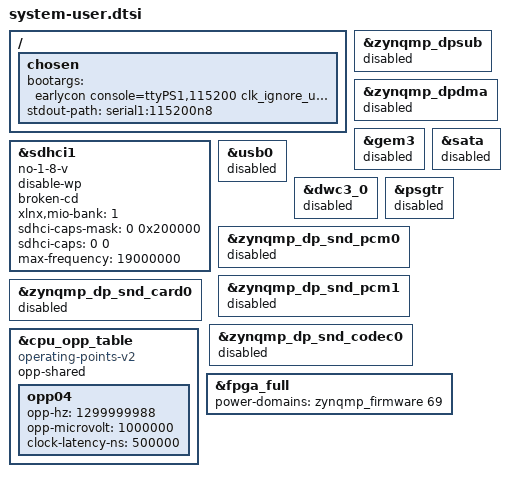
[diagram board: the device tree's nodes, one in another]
/include/ "system-conf.dtsi"
/ {
	chosen {
                bootargs = "earlycon console=ttyPS1,115200 clk_ignore_unused root=/dev/mmcblk1p2 init_fatal_sh=1 cma=1000M ";
                stdout-path = "serial1:115200n8";
        };
};

&sdhci1 { /* FIXME - on CC - MIO 39 - 51 */
    	status = "okay";
    	no-1-8-v;
    	disable-wp;
    	broken-cd;
    	xlnx,mio-bank = <1>;
    	/* Do not run SD in HS mode from bootloader */
    	sdhci-caps-mask = <0 0x200000>;
    	sdhci-caps = <0 0>;
    	max-frequency = <19000000>;
};
    
&zynqmp_dpsub {
	status = "disabled";
	
};

&zynqmp_dpdma {
	status = "disabled";
};

&gem3 {
	status = "disabled";
};

&sata {
	status = "disabled";
};

&usb0 {
        status = "disabled";
};

&dwc3_0 {
        status = "disabled";
};

&psgtr {
        status = "disabled";
};

&zynqmp_dp_snd_pcm0 {
        status = "disabled";
};

&zynqmp_dp_snd_pcm1 {
        status = "disabled";
};

&zynqmp_dp_snd_card0 {
        status = "disabled";
};

&zynqmp_dp_snd_codec0 {
        status = "disabled";
};

&cpu_opp_table {
                compatible = "operating-points-v2";
                opp-shared;
                opp04 {
                        opp-hz = /bits/ 64 <1299999988>;
                        opp-microvolt = <1000000>;
                        clock-latency-ns = <500000>;
                        };
};

&fpga_full {
	power-domains = <&zynqmp_firmware 69>;
};
